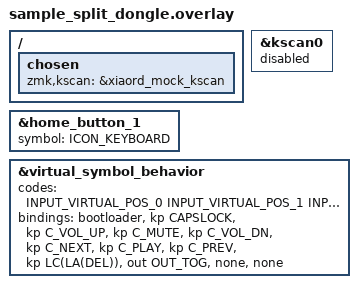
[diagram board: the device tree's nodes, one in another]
#include "sample_split.dtsi"
#include <dt-bindings/xiaord/icons.h>
#include <dt-bindings/zmk/keys.h>
#include <dt-bindings/zmk/outputs.h>

// Dongle has no physical matrix — disable the gpio kscan and use xiaord's mock kscan.
&kscan0 {
    status = "disabled";
};

/ {
    chosen {
        zmk,kscan = &xiaord_mock_kscan;
    };
};

// ============================================================
// ICON_* constant definitions:
//   zmk_modules/zmk-module-xiaord/include/dt-bindings/xiaord/icons.h
//
// Each symbol maps 1:1 to an LVGL LV_SYMBOL_* icon.
// Icon reference: https://docs.lvgl.io/9.0/overview/font.html
// ============================================================
// &home_button_0 { symbol = <ICON_UPLOAD>; };    /* 12 o'clock */
&home_button_1 { symbol = <ICON_KEYBOARD>; };     /*  1 o'clock  */
// &home_button_2 { symbol = <ICON_VOLUME_MAX>; }; /*  2 o'clock */
// &home_button_3 { symbol = <ICON_MUTE>; };       /*  3 o'clock */
// &home_button_4 { symbol = <ICON_VOLUME_MID>; }; /*  4 o'clock */
// &home_button_5 { symbol = <ICON_NEXT>; };       /*  5 o'clock */
// &home_button_6 { symbol = <ICON_PLAY>; };       /*  6 o'clock */
// &home_button_7 { symbol = <ICON_PREV>; };       /*  7 o'clock */
// &home_button_8 { symbol = <ICON_WARNING>; };    /*  8 o'clock */
// &home_button_9 { symbol = <ICON_USB>; };        /*  9 o'clock */
// &home_button_10 { symbol = <ICON_BLUETOOTH>; nav-page = <XIAORD_PAGE_BT>; };    /* 10 o'clock */
// &home_button_11 { symbol = <ICON_SETTINGS>; nav-page = <XIAORD_PAGE_CLOCK>; }; /* 11 o'clock */

&virtual_symbol_behavior {
    codes = <
        INPUT_VIRTUAL_POS_0    INPUT_VIRTUAL_POS_1
        INPUT_VIRTUAL_POS_2    INPUT_VIRTUAL_POS_3
        INPUT_VIRTUAL_POS_4    INPUT_VIRTUAL_POS_5
        INPUT_VIRTUAL_POS_6    INPUT_VIRTUAL_POS_7
        INPUT_VIRTUAL_POS_8    INPUT_VIRTUAL_POS_9
        INPUT_VIRTUAL_POS_10   INPUT_VIRTUAL_POS_11
    >;
    bindings = <
        &bootloader            &kp CAPSLOCK
        &kp C_VOL_UP           &kp C_MUTE
        &kp C_VOL_DN           &kp C_NEXT
        &kp C_PLAY             &kp C_PREV
        &kp LC(LA(DEL))        &out OUT_TOG
        &none                  &none
    >;
};
